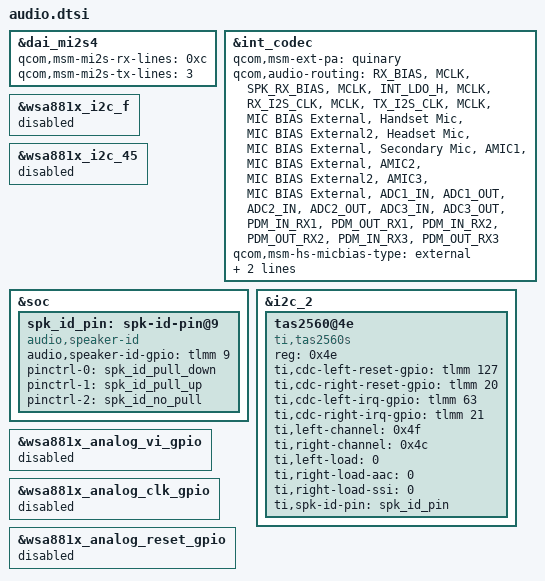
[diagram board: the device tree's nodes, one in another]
/* msm-audio.dtsi */
&dai_mi2s4 {
    qcom,msm-mi2s-rx-lines = <0xc>;
    qcom,msm-mi2s-tx-lines = <3>;
};
&int_codec {
    qcom,msm-ext-pa = "quinary";
    qcom,audio-routing =
            "RX_BIAS", "MCLK",
            "SPK_RX_BIAS", "MCLK",
            "INT_LDO_H", "MCLK",
            "RX_I2S_CLK", "MCLK",
            "TX_I2S_CLK", "MCLK",
            "MIC BIAS External", "Handset Mic",
            "MIC BIAS External2", "Headset Mic",
            "MIC BIAS External", "Secondary Mic",
            "AMIC1", "MIC BIAS External",
            "AMIC2", "MIC BIAS External2",
            "AMIC3", "MIC BIAS External",
            "ADC1_IN", "ADC1_OUT",
            "ADC2_IN", "ADC2_OUT",
            "ADC3_IN", "ADC3_OUT",
            "PDM_IN_RX1", "PDM_OUT_RX1",
            "PDM_IN_RX2", "PDM_OUT_RX2",
            "PDM_IN_RX3", "PDM_OUT_RX3";
    /delete-property/ qcom,hdmi-dba-codec-rx;
    /* delete us_eu_gpio from qcom,msm-gpios list */
};

/* msm8953-audio-mtp.dtsi */
&int_codec {
	qcom,msm-hs-micbias-type = "external";
};
/*
&wsa881x_i2c_e {
	status = "disabled";
};
&wsa881x_i2c_44 {
	status = "disabled";
};
*/
&wsa881x_i2c_f {
	status = "disabled";
};
&wsa881x_i2c_45 {
	status = "disabled";
};

/* msm8953-audio.dtsi */
&int_codec {
    /delete-property/ qcom,cdc-us-euro-gpios;
    /delete-property/ qcom,cdc-us-eu-gpios;
	qcom,msm-mbhc-hphl-swh = <1>;
	qcom,msm-mbhc-gnd-swh = <1>;
	qcom,msm-hs-micbias-type = "external";
    /* GPIO changes, will have to figure it out later */
    /* hdmi-dba doesn't exist on k4.9 asoc-codec */
    /delete-property/ asoc-wsa-codec-names;
    /delete-property/ asoc-wsa-codec-prefixes;
    /delete-property/ msm-vdd-wsa-switch-supply;
    /delete-property/ qcom,msm-vdd-wsa-switch-voltage;
    /delete-property/ qcom,msm-vdd-wsa-switch-current;
};

/* msm8953-oxygen.dtsi */
&soc {
	spk_id_pin: spk-id-pin@9 {
		compatible = "audio,speaker-id";
		audio,speaker-id-gpio = <&tlmm 9 0x00>;
		pinctrl-names = "pull_down", "pull_up", "no_pull";
		pinctrl-0 = <&spk_id_pull_down>;
		pinctrl-1 = <&spk_id_pull_up>;
		pinctrl-2 = <&spk_id_no_pull>;
	};
};
&i2c_2 { /* BLSP2 QUP1 (TAS2560) */
	tas2560@4e {
		compatible = "ti,tas2560s";
		reg = <0x4e>;
		ti,cdc-left-reset-gpio = <&tlmm 127 0>;
		ti,cdc-right-reset-gpio = <&tlmm 20 0>;
		ti,cdc-left-irq-gpio = <&tlmm 63 0>;
		ti,cdc-right-irq-gpio = <&tlmm 21 0>;
		ti,left-channel = <0x4f>;
		ti,right-channel = <0x4c>;
		ti,left-load = <0>;   /* 0, 8Ohm; 1, 6Ohm; 2, 4Ohm */
		ti,right-load-aac = <0>;   /* 0, 8Ohm; 1, 6Ohm; 2, 4Ohm */
		ti,right-load-ssi = <0>;   /* 0, 8Ohm; 1, 6Ohm; 2, 4Ohm */
		ti,spk-id-pin = <&spk_id_pin>;

	};
};

/* Custom changes */
&wsa881x_analog_vi_gpio {
        status = "disabled";
};

&wsa881x_analog_clk_gpio {
        status = "disabled";
};

&wsa881x_analog_reset_gpio {
        status = "disabled";
};
